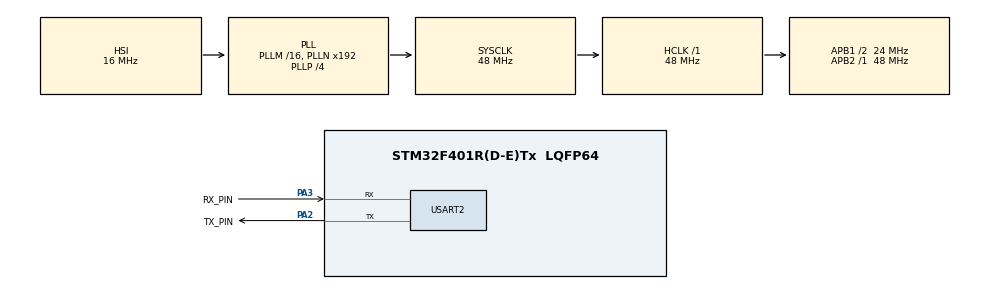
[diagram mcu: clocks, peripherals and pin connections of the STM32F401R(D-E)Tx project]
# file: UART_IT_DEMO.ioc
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Mcu.Family=STM32F4
Mcu.Name=STM32F401R(D-E)Tx
Mcu.Package=LQFP64
NVIC.PriorityGroup=NVIC_PRIORITYGROUP_4
NVIC.USART2_IRQn=true\:1\:0\:true\:false\:true\:true
PA2.GPIO_Label=TX_PIN
PA2.Mode=Asynchronous
PA2.Signal=USART2_TX
PA3.GPIO_Label=RX_PIN
PA3.Mode=Asynchronous
PA3.Signal=USART2_RX
ProjectManager.HeapSize=0x200
ProjectManager.StackSize=0x400
ProjectManager.TargetToolchain=MDK-ARM V5
RCC.AHBFreq_Value=48000000
RCC.APB1CLKDivider=RCC_HCLK_DIV2
RCC.APB1Freq_Value=24000000
RCC.APB1TimFreq_Value=48000000
RCC.APB2Freq_Value=48000000
RCC.APB2TimFreq_Value=48000000
RCC.CortexFreq_Value=48000000
RCC.HCLKFreq_Value=48000000
RCC.HSE_VALUE=25000000
RCC.HSI_VALUE=16000000
RCC.LSE_VALUE=32768
RCC.PLLP=RCC_PLLP_DIV4
RCC.SYSCLKFreq_VALUE=48000000
RCC.SYSCLKSource=RCC_SYSCLKSOURCE_PLLCLK
RCC.VCOOutputFreq_Value=192000000
USART2.VirtualMode=VM_ASYNC
board=UART_IT_DEMO

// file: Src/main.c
/**
  ******************************************************************************
  * File Name          : main.c
  * Description        : Main program body
  ******************************************************************************
  ** This notice applies to any and all portions of this file
  * that are not between comment pairs USER CODE BEGIN and
  * USER CODE END. Other portions of this file, whether
  * inserted by the user or by software development tools
  * are owned by their respective copyright owners.
  *
  * COPYRIGHT(c) 2018 STMicroelectronics
  *
  * Redistribution and use in source and binary forms, with or without modification,
  * are permitted provided that the following conditions are met:
  *   1. Redistributions of source code must retain the above copyright notice,
  *      this list of conditions and the following disclaimer.
  *   2. Redistributions in binary form must reproduce the above copyright notice,
  *      this list of conditions and the following disclaimer in the documentation
  *      and/or other materials provided with the distribution.
  *   3. Neither the name of STMicroelectronics nor the names of its contributors
  *      may be used to endorse or promote products derived from this software
  *      without specific prior written permission.
  *
  * THIS SOFTWARE IS PROVIDED BY THE COPYRIGHT HOLDERS AND CONTRIBUTORS "AS IS"
  * AND ANY EXPRESS OR IMPLIED WARRANTIES, INCLUDING, BUT NOT LIMITED TO, THE
  * IMPLIED WARRANTIES OF MERCHANTABILITY AND FITNESS FOR A PARTICULAR PURPOSE ARE
  * DISCLAIMED. IN NO EVENT SHALL THE COPYRIGHT HOLDER OR CONTRIBUTORS BE LIABLE
  * FOR ANY DIRECT, INDIRECT, INCIDENTAL, SPECIAL, EXEMPLARY, OR CONSEQUENTIAL
  * DAMAGES (INCLUDING, BUT NOT LIMITED TO, PROCUREMENT OF SUBSTITUTE GOODS OR
  * SERVICES; LOSS OF USE, DATA, OR PROFITS; OR BUSINESS INTERRUPTION) HOWEVER
  * CAUSED AND ON ANY THEORY OF LIABILITY, WHETHER IN CONTRACT, STRICT LIABILITY,
  * OR TORT (INCLUDING NEGLIGENCE OR OTHERWISE) ARISING IN ANY WAY OUT OF THE USE
  * OF THIS SOFTWARE, EVEN IF ADVISED OF THE POSSIBILITY OF SUCH DAMAGE.
  *
  ******************************************************************************
  */

#include "main.h"
#include "stm32f4xx_hal.h"
#include "usart.h"
#include "gpio.h"

/* USER CODE BEGIN PV */
/* Private variables ---------------------------------------------------------*/

/* USER CODE END PV */

void SystemClock_Config(void);

/* USER CODE BEGIN PFP */
/* Private function prototypes -----------------------------------------------*/
extern UART_HandleTypeDef huart2;
/* USER CODE END PFP */

/* USER CODE BEGIN 0 */
uint8_t Rx_data[64];
char Rx_txt[20]="this is Txt";
/* USER CODE END 0 */

int main(void)
{

  /* MCU Configuration----------------------------------------------------------*/

  /* Reset of all peripherals, Initializes the Flash interface and the Systick. */
  HAL_Init();

  /* Configure the system clock */
  SystemClock_Config();

  /* Initialize all configured peripherals */
  MX_GPIO_Init();
  MX_USART2_UART_Init();

  /* USER CODE BEGIN 2 */
	printf("this is UART_IT_DEMO\r\n");
  /* USER CODE END 2 */

  /* Infinite loop */
  while (1)
  {

  /* USER CODE BEGIN 3 */
   printf("this is Test_IDLE\r\n");
	 HAL_Delay(2000);
  }
  /* USER CODE END 3 */

}

/** System Clock Configuration
*/
void SystemClock_Config(void)
{

  RCC_OscInitTypeDef RCC_OscInitStruct;
  RCC_ClkInitTypeDef RCC_ClkInitStruct;

    /**Configure the main internal regulator output voltage
    */
  __HAL_RCC_PWR_CLK_ENABLE();

  __HAL_PWR_VOLTAGESCALING_CONFIG(PWR_REGULATOR_VOLTAGE_SCALE2);

    /**Initializes the CPU, AHB and APB busses clocks
    */
  RCC_OscInitStruct.OscillatorType = RCC_OSCILLATORTYPE_HSI;
  RCC_OscInitStruct.HSIState = RCC_HSI_ON;
  RCC_OscInitStruct.HSICalibrationValue = 16;
  RCC_OscInitStruct.PLL.PLLState = RCC_PLL_ON;
  RCC_OscInitStruct.PLL.PLLSource = RCC_PLLSOURCE_HSI;
  RCC_OscInitStruct.PLL.PLLM = 16;
  RCC_OscInitStruct.PLL.PLLN = 192;
  RCC_OscInitStruct.PLL.PLLP = RCC_PLLP_DIV4;
  RCC_OscInitStruct.PLL.PLLQ = 4;
  if (HAL_RCC_OscConfig(&RCC_OscInitStruct) != HAL_OK)
  {
    _Error_Handler(__FILE__, __LINE__);
  }

    /**Initializes the CPU, AHB and APB busses clocks
    */
  RCC_ClkInitStruct.ClockType = RCC_CLOCKTYPE_HCLK|RCC_CLOCKTYPE_SYSCLK
                              |RCC_CLOCKTYPE_PCLK1|RCC_CLOCKTYPE_PCLK2;
  RCC_ClkInitStruct.SYSCLKSource = RCC_SYSCLKSOURCE_PLLCLK;
  RCC_ClkInitStruct.AHBCLKDivider = RCC_SYSCLK_DIV1;
  RCC_ClkInitStruct.APB1CLKDivider = RCC_HCLK_DIV2;
  RCC_ClkInitStruct.APB2CLKDivider = RCC_HCLK_DIV1;

  if (HAL_RCC_ClockConfig(&RCC_ClkInitStruct, FLASH_LATENCY_1) != HAL_OK)
  {
    _Error_Handler(__FILE__, __LINE__);
  }

    /**Configure the Systick interrupt time
    */
  HAL_SYSTICK_Config(HAL_RCC_GetHCLKFreq()/1000);

    /**Configure the Systick
    */
  HAL_SYSTICK_CLKSourceConfig(SYSTICK_CLKSOURCE_HCLK);

  /* SysTick_IRQn interrupt configuration */
  HAL_NVIC_SetPriority(SysTick_IRQn, 0, 0);
}

/* USER CODE BEGIN 4 */
void HAL_UART_RxCpltCallback(UART_HandleTypeDef *huart)
{
	if (huart->Instance == USART2)
  {
		HAL_UART_Transmit(&huart2, (uint8_t *)Rx_data, 10,0xFFFF);
	}
}

/* USER CODE END 4 */

void _Error_Handler(char * file, int line)
{
  while(1)
  {
  }
}

/************************ (C) COPYRIGHT STMicroelectronics *****END OF FILE****/
